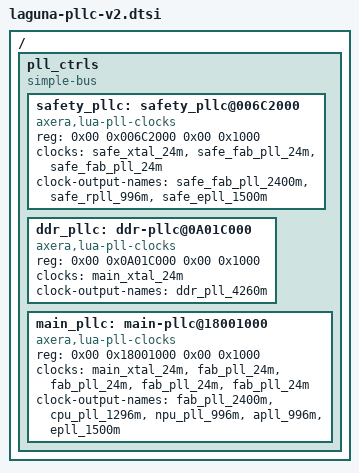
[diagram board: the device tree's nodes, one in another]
/* SPDX-License-Identifier: GPL-2.0+
 *
 * Device Tree Source (V2) for Laguna PLL Ctrl
 *
 * Copyright (C) 2024 Charleye <wangkart@aliyun.com>
 */

/ {
	pll_ctrls {
		compatible = "simple-bus";
		#address-cells = <2>;
		#size-cells = <2>;

		safety_pllc: safety_pllc@006C2000 {
			compatible = "axera,lua-pll-clocks";
			reg = <0x00 0x006C2000 0x00 0x1000>;
			#clock-cells = <1>;
			clocks = <&safe_xtal_24m>, <&safe_fab_pll_24m>,
			         <&safe_fab_pll_24m>;
			clock-names = "safe_xtal_24m", "safe_fab_pll_24m",
			              "safe_fab_pll_24m";
			clock-output-names = "safe_fab_pll_2400m", "safe_rpll_996m",
			                     "safe_epll_1500m";
		};

		ddr_pllc: ddr-pllc@0A01C000 {
			compatible = "axera,lua-pll-clocks";
			reg = <0x00 0x0A01C000 0x00 0x1000>;
			#clock-cells = <1>;
			clocks = <&main_xtal_24m>;
			clock-names = "main_xtal_24m";
			clock-output-names = "ddr_pll_4260m";
		};

		main_pllc: main-pllc@18001000 {
			compatible = "axera,lua-pll-clocks";
			reg = <0x00 0x18001000 0x00 0x1000>;
			#clock-cells = <1>;
			clocks = <&main_xtal_24m>, <&fab_pll_24m>,
			         <&fab_pll_24m>, <&fab_pll_24m>,
			         <&fab_pll_24m>;
			clock-names = "main_xtal_24m", "fab_pll_24m",
			              "fab_pll_24m", "fab_pll_24m",
			               "fab_pll_24m";
			clock-output-names = "fab_pll_2400m", "cpu_pll_1296m",
			                     "npu_pll_996m", "apll_996m",
			                     "epll_1500m";
		};
	};
};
